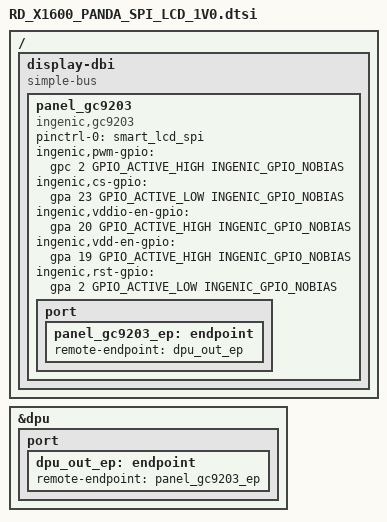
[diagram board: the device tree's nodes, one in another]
/ {

	display-dbi {
		compatible = "simple-bus";
		#interrupt-cells = <1>;
		#address-cells = <1>;
		#size-cells = <1>;
		ranges = <>;
		panel_gc9203 {
			compatible = "ingenic,gc9203";
			status = "okay";
			pinctrl-names = "default";
			pinctrl-0 = <&smart_lcd_spi>;
			ingenic,pwm-gpio = <&gpc 2 GPIO_ACTIVE_HIGH INGENIC_GPIO_NOBIAS>;
			ingenic,cs-gpio = <&gpa 23 GPIO_ACTIVE_LOW INGENIC_GPIO_NOBIAS>;
			ingenic,vddio-en-gpio = <&gpa 20 GPIO_ACTIVE_HIGH INGENIC_GPIO_NOBIAS>;
			ingenic,vdd-en-gpio = <&gpa 19 GPIO_ACTIVE_HIGH INGENIC_GPIO_NOBIAS>;
			ingenic,rst-gpio = <&gpa 2 GPIO_ACTIVE_LOW INGENIC_GPIO_NOBIAS>;
			port {
				panel_gc9203_ep: endpoint {
					remote-endpoint = <&dpu_out_ep>;
				};
			};
		};
	};

};

&dpu {
	port {
		dpu_out_ep: endpoint {
		remote-endpoint = <&panel_gc9203_ep>;
	    };
	};
};

